# WKUP_CTRL_MMR0_WKUP_CTRL_MMR0_CLK_MMRS_43020000h register map
Vendor: Texas Instruments
Peripheral module from a debugger description file (folder am62L).
Registers are 32-bit, read-write, reset 0x0 unless marked. A register's access mark holds for its fields unless they carry their own. Offsets are as the file gives them; lines under a group give offsets from that group; [hi:lo] are bit positions; {n}, {i} and the like mark numbered series; 'fields as' and 'values as' point back to an identical list; <NAME> marks a mode.

## WKUP_CTRL_MMR0_CLK_MMRS
0x100 WKUP_CTRL_MMR0_CLK_MMRS_CLK_32K_RC_CLKSEL — Selects which clock sourced DEVICE_CLKOUT_32K
  [1:0] CLK_32K_RC_CLKSEL_CLK_SEL — Clock source for DEVICE_CLKOUT_32K 1 HFOSC0_CLKOUT_32K2 CLK_32K_RC3 LFOSC0_CLKOUT
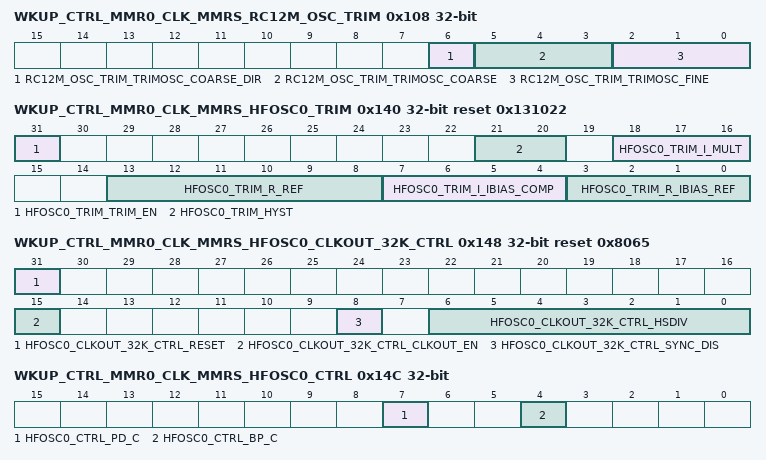
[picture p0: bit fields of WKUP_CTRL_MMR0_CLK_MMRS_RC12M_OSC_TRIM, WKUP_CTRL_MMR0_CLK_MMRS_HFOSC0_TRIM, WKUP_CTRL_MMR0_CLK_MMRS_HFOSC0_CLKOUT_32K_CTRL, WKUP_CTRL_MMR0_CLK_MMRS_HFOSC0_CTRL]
0x108 WKUP_CTRL_MMR0_CLK_MMRS_RC12M_OSC_TRIM — Provides frequency trimming for the 12.5 MHz RC oscillator module
  [6] RC12M_OSC_TRIM_TRIMOSC_COARSE_DIR — Coarse adjustment direction. If output is greater than 12.5 0 - Coarse adjustment decreases frequency 1 - Coarse adjustment increases frequency 0 TRIM_FREQ_LOWER1 TRIM_FREQ_HIGHER
  [5:3] RC12M_OSC_TRIM_TRIMOSC_COARSE — Coarse adjustment. Frequency is decreased or increased by 1.25 MHz per value based on the trimosc_coarse_dir value. 0 TRIM_0_MHZ1 TRIM_1P25_MHZ2 TRIM_2P50_MHZ3 TRIM_3P75_MHZ4 TRIM_4P00_MHZ5 TRIM_5P25_MHZ6 TRIM_6P50_MHZ7 TRIM_7P75_MHZ
  [2:0] RC12M_OSC_TRIM_TRIMOSC_FINE — Fine adjustment. Decreases the frequency by 250 KHz per value. 0 TRIM_0_KHZ1 TRIM_250_KHZ2 TRIM_500_KHZ3 TRIM_750_KHZ4 TRIM_1000_KHZ5 TRIM_1250_KHZ6 TRIM_1500_KHZ7 TRIM_1750_KHZ
0x140 WKUP_CTRL_MMR0_CLK_MMRS_HFOSC0_TRIM reset 0x131022 — Provides frequency trimming for oscillator 0
  [31] HFOSC0_TRIM_TRIM_EN — Apply MMR values to OSC trim inputs instead of tie-offs 0 FIXED_TRIM1 MMR_TRIM
  [21:20] HFOSC0_TRIM_HYST — Sets comparator hysterisis 0 NO_HYS1 TYPE1_HYS2 TYPE2_HYS3 BOTH_TYPES_HYS
  [18:16] HFOSC0_TRIM_I_MULT — AGC AMP current multiplication gain 0 GAIN_0P250X1 GAIN_0P375X2 GAIN_0P500X3 GAIN_0P625X4 GAIN_0P750X5 GAIN_0P875X6 GAIN_1X7 GAIN_1P250X
  [13:8] HFOSC0_TRIM_R_REF — Sets the AMP AGC bias current 0 R_REF_4X8 R_REF_6X16 R_REF_8X24 R_REF_10X32 R_REF_12X40 R_REF_14X48 R_REF_16X56 R_REF_18X
  [7:4] HFOSC0_TRIM_I_IBIAS_COMP — Sets the COMP bias current 0 I_BIAS_COMP_2P00X1 I_BIAS_COMP_2P25X2 I_BIAS_COMP_2P50X3 I_BIAS_COMP_2P75X4 I_BIAS_COMP__2P50X5 I_BIAS_COMP__2P75X6 I_BIAS_COMP_3P00X7 I_BIAS_COMP_3P25X8 I_BIAS_COMP__3P00X9 I_BIAS_COMP__3P25X12 I_BIAS_COMP_3P50X13 I_BIAS_COMP_3P75X14 I_BIAS_COMP_4P00X15 I_BIAS_COMP_4P25X
  [3:0] HFOSC0_TRIM_R_IBIAS_REF — Sets the base IBIAS reference 0 IBIAS_REF_1X1 IBIAS_REF_5X3 IBIAS_REF_7X
0x148 WKUP_CTRL_MMR0_CLK_MMRS_HFOSC0_CLKOUT_32K_CTRL reset 0x8065 — Controls the HSDIV that generates a 32KHz RT clock from the HFOSC0 Crystal
  [31] HFOSC0_CLKOUT_32K_CTRL_RESET — Asynchronous Divider Reset. 0 ACTIVE1 RESET
  [15] HFOSC0_CLKOUT_32K_CTRL_CLKOUT_EN — HFOSC0_CLKOUT_32K output active 0 INACTIVE1 ACTIVE
  [8] HFOSC0_CLKOUT_32K_CTRL_SYNC_DIS — HFOSC0_CLKOUT_32K Synchronize DeactivateThis bit must be written 0. 0 NORMAL
  [6:0] HFOSC0_CLKOUT_32K_CTRL_HSDIV — HFOSC0_CLKOUT_32K divider:HFOSC0_CLKKOUT_32K Frequency = HFOSC0 Frequency / [8 * (hsdiv + 1)]Ex. HFOSC0 Frequency = 26MHz. hsdiv = 101 (Default)HFOSC0_CLKOUT_32K = 26MHz / (8 * (101+1)) = 26MHz / 816 = 31.9 KHz Reset Source: mod_por_rst_n
0x14C WKUP_CTRL_MMR0_CLK_MMRS_HFOSC0_CTRL — Controls the operation of oscillator 0
  [7] HFOSC0_CTRL_PD_C — Oscillator powerdown control. 0 ACTIVE1 POWERDOWN
  [4] HFOSC0_CTRL_BP_C — Must Write '0' Reset Source: mod_por_rst_n
0x200 WKUP_CTRL_MMR0_CLK_MMRS_WKUP_OBSCLK0_CLKSEL — Selects clock source for WKUP OBSCLK0 pin divider input
  [3:0] WKUP_OBSCLK0_CLKSEL_CLK_SEL — Controls the WKUP OBSCLK0 Mux Input to Divider 0 CLK_12M_RC1 TIE02 WKUP_PLL0_HSDIV0_CLKOUT3 WKUP_PLL0_HSDIV4_CLKOUT4 WKUP_PLLCTRL_OBSCLK5 CLK_32K_RC6 HFOSC0_CLKOUT7 HFOSC0_CLKOUT_32K8 WKUP_SYSCLK09 DEVICE_CLKOUT_32K10 WKUP_PLL0_HSDIV8_CLKOUT
0x204 WKUP_CTRL_MMR0_CLK_MMRS_WKUP_OBSCLK0_OUTMUX_SEL — Selects clock source for WKUP OBSCLK0 pin final mux
  [0] WKUP_OBSCLK0_OUTMUX_SEL_CLK_SEL — Controls the Final WKUP OBSCLK0 pin mux 0 HFOSC0_CLK1 WKUP_OBSCLK_MUX_SEL_DIVX
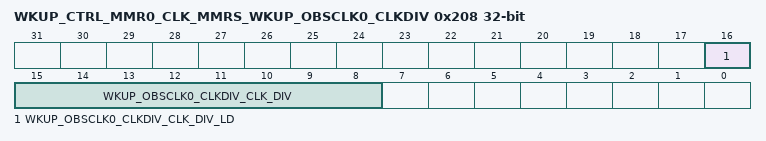
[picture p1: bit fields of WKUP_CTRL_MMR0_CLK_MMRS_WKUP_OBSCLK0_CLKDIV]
0x208 WKUP_CTRL_MMR0_CLK_MMRS_WKUP_OBSCLK0_CLKDIV — This register controls the output divider value for the WKUP_OBSCLK0 output pin
  [16] WKUP_OBSCLK0_CLKDIV_CLK_DIV_LD — Load the output divider valueWriting 1 to this bit will generate a load pulse to load the OBSCLK0 divider value. This bit can be cleared but must not be set in the same write cycle in which the clk_div value is changed. 0 READY1 LOAD
  [15:8] WKUP_OBSCLK0_CLKDIV_CLK_DIV — OBSCLK0 output dividerDivides the selected clock by clkdiv+1 for output to the OBSCLK0 pins. Supports divide by 1 to 256 (default to 1). To load the new divider value the clk_div_ld bit must be cleared and then set to 1. 0 DIV11 DIV22 DIV33 DIV44 DIV55 DIV66 DIV77 DIV88 DIV99 DIV1010 DIV1111 DIV1212 DIV1313 DIV1414 DIV1515 DIV16
0x1000 WKUP_CTRL_MMR0_CLK_MMRS_WKUP_GTC_OUTMUX_SEL — Selects the timebase clock source for the Global Timebase Counter - Final Mux
  [0] WKUP_GTC_OUTMUX_SEL_CLK_SEL — Selects the final stage GTC timebase clock source. This selection is implemented with a glitch free clock mux and may be changed dynamically between the output of the first stage mux (WKUP_GTC_CLKSEL) and DEVICE_CLKOUT_32K 0 WKUP_GTC_CLKSEL_OUT1 DEVICE_CLKOUT_32K
0x2000 WKUP_CTRL_MMR0_CLK_MMRS_WKUP_TIMER0_CLKSEL — Timer0 functional clock selection control
  [2:0] WKUP_TIMER0_CLKSEL_CLK_SEL — Timer functional clock input select mux control 0 HFOSC0_CLKOUT1 PER_SYSCLK0_DIV22 CLK_12M_RC3 WKUP_PLL0_HSDIV7_CLKOUT5 DEVICE_CLKOUT_32K6 CPSW0_CPTS_GENF07 CLK_32K_RC
0x2004 WKUP_CTRL_MMR0_CLK_MMRS_WKUP_TIMER1_CLKSEL — Timer1 functional clock selection control
  [2:0] WKUP_TIMER1_CLKSEL_CLK_SEL — Timer functional clock input select mux control 0 HFOSC0_CLKOUT1 PER_SYSCLK0_DIV22 CLK_12M_RC3 WKUP_PLL0_HSDIV7_CLKOUT5 DEVICE_CLKOUT_32K6 CPSW0_CPTS_GENF07 CLK_32K_RC
0x3000 WKUP_CTRL_MMR0_CLK_MMRS_WKUP_CLKOUT_SEL — Controls the WKUP_CLKOUT0 pin mux
  [2:0] WKUP_CLKOUT_SEL_CLK_SEL — Controls the WKUP_CLKOUT0 Pin Selection 0 TIE01 LFOSC0_CLKOUT2 WKUP_PLL0_HSDIV7_CLKOUT3 WKUP_SYSCLK04 WKUP_PLL0_HSDIV8_CLKOUT5 DEVICE_CLKOUT_32K6 CLK_12M_RC7 HFOSC0_CLK
0x3004 WKUP_CTRL_MMR0_CLK_MMRS_WKUP_CLKOUTMUX_SEL — Controls the final WKUP_CLKOUT0 pin mux
  [0] WKUP_CLKOUTMUX_SEL_CLK_SEL — Controls the Final WKUP CLKOUT pin mux 0 HFOSC0_CLK1 WKUP_CLKOUT_SEL_MUX
0x4000 WKUP_CTRL_MMR0_CLK_MMRS_WKUP_GTC_CLKSEL reset 0x1 — Selects the timebase clock source for the Global Timebase Counter - First Mux
  [2:0] WKUP_GTC_CLKSEL_CLK_SEL — Selects the First Stage GTC timebase clock source - This field may not be changed while the GTC is in use as the mux that implements the stage is not glitch free. 1 MAIN_PLL0_HSDIV7_CLKOUT6 PER_SYSCLK0_DIV20 WKUP_PLL0_HSDIV7_CLKOUT0xNaN undefined
0x5000 WKUP_CTRL_MMR0_CLK_MMRS_USB0_CLKSEL — Selects the functional clock sources for USB0
  [0] USB0_CLKSEL_REFCLK_SEL — Selects the clock source for the USB0 ref_clk. 0 HFOSC0_CLKOUT1 MAIN_PLL0_HSDIV8_CLKOUT_DIV4
0x5004 WKUP_CTRL_MMR0_CLK_MMRS_USB1_CLKSEL — Selects the functional clock sources for USB1
  [0] USB1_CLKSEL_REFCLK_SEL — Selects the clock source for the USB1 ref_clk. 0 HFOSC0_CLKOUT1 MAIN_PLL0_HSDIV8_CLKOUT_DIV4
0x5100 WKUP_CTRL_MMR0_CLK_MMRS_USB0_PHY_CLKSEL reset 0x6 — Selects the reference clock source for USB0 PHY
  [3:0] USB0_PHY_CLKSEL_REFCLK_SEL — Indicates the frequency of the REF_CLOCK input used by the USB PLL. This value should be set to match the frequency of the USB0 input clock, as selected by the USB0_CLKSEL Register. 0 MHZ_9P61 MHZ_102 MHZ_123 MHZ_19P24 MHZ_205 MHZ_246 MHZ_257 MHZ_268 MHZ_38P49 MHZ_4010 MHZ_4811 MHZ_5012 MHZ_52
0x5104 WKUP_CTRL_MMR0_CLK_MMRS_USB1_PHY_CLKSEL reset 0x6 — Selects the reference clock source for USB1 PHY
  [3:0] USB1_PHY_CLKSEL_REFCLK_SEL — Indicates the frequency of the REF_CLOCK input used by the USB PLL. This value should be set to match the frequency of the USB0 input clock, as selected by the USB1_CLKSEL Register. 0 MHZ_9P61 MHZ_102 MHZ_123 MHZ_19P24 MHZ_205 MHZ_246 MHZ_257 MHZ_268 MHZ_38P49 MHZ_4010 MHZ_4811 MHZ_5012 MHZ_52
0x8000 WKUP_CTRL_MMR0_CLK_MMRS_WKUP_GPIO0_CLKSEL — Selects the bus interface clock source for the WKUP Domain GPIO0 Module
  [1:0] WKUP_GPIO0_CLKSEL_CLK_SEL — Selects Bus Interface Clock Source for Wakeup Domain GPIO Module 0 PER_SYSCLK0_DIV41 LFOSC0_CLKOUT2 CLK_32K3 CLK_12M_RC
0xF000 WKUP_CTRL_MMR0_CLK_MMRS_EFUSE_CLKSEL — Selects the functional clock source for the MAIN domain eFuse Controller
  [0] EFUSE_CLKSEL_CLK_SEL — Selects the clock source 0 HFOSC0_CLKOUT1 MAIN_SYSCLK0/12
